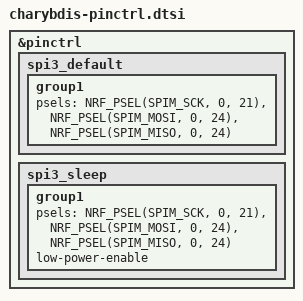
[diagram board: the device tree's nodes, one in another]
&pinctrl {
	spi3_default: spi3_default {
		group1 {
			psels = <NRF_PSEL(SPIM_SCK, 0, 21)>,
				<NRF_PSEL(SPIM_MOSI, 0, 24)>,
				<NRF_PSEL(SPIM_MISO, 0, 24)>;
		};
	};

	spi3_sleep: spi3_sleep {
		group1 {
			psels = <NRF_PSEL(SPIM_SCK, 0, 21)>,
				<NRF_PSEL(SPIM_MOSI, 0, 24)>,
				<NRF_PSEL(SPIM_MISO, 0, 24)>;
			low-power-enable;
		};
	};

};
